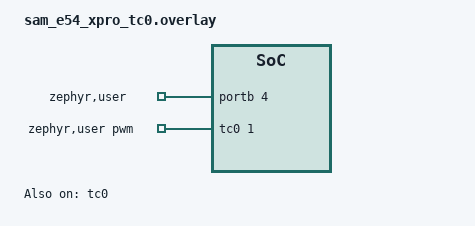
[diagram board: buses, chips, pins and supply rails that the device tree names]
/*
 * Copyright (c) 2025 Microchip Technology Inc.
 *
 * SPDX-License-Identifier: Apache-2.0
 */

/* connect the PA05 to PB04 */

#include <zephyr/dt-bindings/gpio/gpio.h>

/ {
	zephyr,user {
		pwms = <&tc0 1 PWM_MSEC(20) 0>;
		gpios = <&portb 4 GPIO_ACTIVE_HIGH>;
	};
};

&tc0 {
	status = "okay";
};

&pinctrl {
	tc0_pwm_default: tc0_pwm_default {
		group1 {
			pinmux = <PA5E_TC0_WO1>;
		};
	};
};
